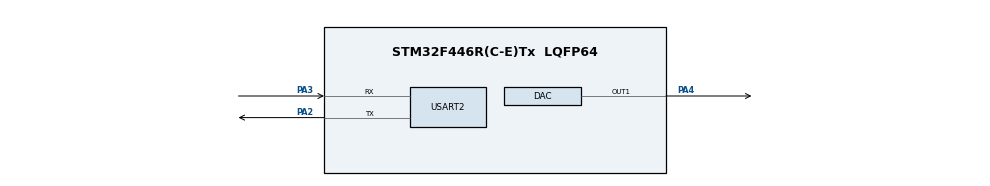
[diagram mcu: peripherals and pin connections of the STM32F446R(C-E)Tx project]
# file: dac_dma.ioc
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DAC.DAC_Trigger=DAC_TRIGGER_T6_TRGO
Dma.DAC1.0.Direction=DMA_MEMORY_TO_PERIPH
Dma.DAC1.0.FIFOMode=DMA_FIFOMODE_DISABLE
Dma.DAC1.0.Instance=DMA1_Stream5
Dma.DAC1.0.MemDataAlignment=DMA_MDATAALIGN_HALFWORD
Dma.DAC1.0.MemInc=DMA_MINC_ENABLE
Dma.DAC1.0.Mode=DMA_CIRCULAR
Dma.DAC1.0.PeriphDataAlignment=DMA_PDATAALIGN_HALFWORD
Dma.DAC1.0.PeriphInc=DMA_PINC_DISABLE
Dma.DAC1.0.Priority=DMA_PRIORITY_LOW
Dma.Request0=DAC1
Mcu.Family=STM32F4
Mcu.Name=STM32F446R(C-E)Tx
Mcu.Package=LQFP64
NVIC.DMA1_Stream5_IRQn=true\:0\:0\:false\:false\:true\:false\:true\:true
NVIC.PriorityGroup=NVIC_PRIORITYGROUP_4
NVIC.TIM6_DAC_IRQn=true\:0\:0\:false\:false\:true\:true\:true\:true
PA13.Mode=Serial_Wire
PA13.Signal=SYS_JTMS-SWDIO
PA14.Mode=Serial_Wire
PA14.Signal=SYS_JTCK-SWCLK
PA2.Mode=Asynchronous
PA2.Signal=USART2_TX
PA3.Mode=Asynchronous
PA3.Signal=USART2_RX
PA4.Signal=COMP_DAC1_group
ProjectManager.HeapSize=0x200
ProjectManager.StackSize=0x400
ProjectManager.TargetToolchain=STM32CubeIDE
RCC.CortexFreq_Value=16000000
RCC.USBFreq_Value=96000000
RCC.VCOOutputFreq_Value=192000000
SH.COMP_DAC1_group.0=DAC_OUT1,DAC_OUT1
TIM6.Period=999
TIM6.Prescaler=15
TIM6.TIM_MasterOutputTrigger=TIM_TRGO_UPDATE
USART2.VirtualMode=VM_ASYNC
VP_TIM6_VS_ClockSourceINT.Mode=Enable_Timer
board=custom

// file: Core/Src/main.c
/* USER CODE BEGIN Header */
/**
  ******************************************************************************
  * @file           : main.c
  * @brief          : Main program body
  ******************************************************************************
  * @attention
  *
  * Copyright (c) 2026 STMicroelectronics.
  * All rights reserved.
  *
  * This software is licensed under terms that can be found in the LICENSE file
  * in the root directory of this software component.
  * If no LICENSE file comes with this software, it is provided AS-IS.
  *
  ******************************************************************************
  */
/* USER CODE END Header */
#include "main.h"

/* USER CODE BEGIN Includes */

#include <stdio.h>
#include <math.h>

/* USER CODE END Includes */

/* USER CODE BEGIN PD */
#define DMA_BUFFER_SIZE 32
#define SAMPLE_FREQ 10000
#define OUTPUT_MID 2048
/* USER CODE END PD */

DAC_HandleTypeDef hdac;
DMA_HandleTypeDef hdma_dac1;

TIM_HandleTypeDef htim6;

UART_HandleTypeDef huart2;

/* USER CODE BEGIN PV */

volatile uint32_t callbck_cnt = 0;
volatile uint32_t cb_cplt;
volatile uint32_t cb_half;

uint16_t dma_buffer[2 * DMA_BUFFER_SIZE];

float angle = 0;
float angle_change = 10 * (2 * M_PI / SAMPLE_FREQ);
const float two_pi = 2 *M_PI;

/* USER CODE END PV */

void SystemClock_Config(void);
static void MX_GPIO_Init(void);
static void MX_DMA_Init(void);
static void MX_USART2_UART_Init(void);
static void MX_DAC_Init(void);
static void MX_TIM6_Init(void);

/* USER CODE BEGIN 0 */

// Send printf to uart2
int _write(int fd, char* ptr, int len) {
  HAL_StatusTypeDef hstatus;

  if (fd == 1 || fd == 2) {
    hstatus = HAL_UART_Transmit(&huart2, (uint8_t *) ptr, len, HAL_MAX_DELAY);
    if (hstatus == HAL_OK)
      return len;
    else
      return -1;
  }
  return -1;
}

inline void HAL_TIM_PeriodElapsedCallback(TIM_HandleTypeDef *htim) {

	if (htim->Instance == TIM6) {
		++callbck_cnt;
	}
}

static inline void do_dac(uint16_t *buffer) {
	for (int i = 0; i < DMA_BUFFER_SIZE; ++i) {
		buffer[i] = OUTPUT_MID - (OUTPUT_MID * cos(angle));
		angle += angle_change;
		if (angle >= two_pi) {
			angle -= two_pi;
		}
	}

}

inline void HAL_DAC_ConvHalfCpltCallbackCh1(DAC_HandleTypeDef *hdac) {
	++cb_half;
	do_dac(&dma_buffer[0]);
}

inline void HAL_DAC_ConvCpltCallbackCh1(DAC_HandleTypeDef *hdac) {
	++cb_cplt;
	do_dac(&dma_buffer[DMA_BUFFER_SIZE]);
}

/* USER CODE END 0 */

int main(void)
{

  /* MCU Configuration--------------------------------------------------------*/

  /* Reset of all peripherals, Initializes the Flash interface and the Systick. */
  HAL_Init();

  /* Configure the system clock */
  SystemClock_Config();

  /* Initialize all configured peripherals */
  MX_GPIO_Init();
  MX_DMA_Init();
  MX_USART2_UART_Init();
  MX_DAC_Init();
  MX_TIM6_Init();
  /* USER CODE BEGIN 2 */

  printf("\n\n\n\n\r------------\n\rStarting DAC\n\r");

  HAL_TIM_Base_Start_IT(&htim6);

  HAL_DAC_Start_DMA(&hdac, DAC_CHANNEL_1, (uint32_t*) &dma_buffer, 2 * DMA_BUFFER_SIZE, DAC_ALIGN_12B_R);

  /* USER CODE END 2 */

  /* Infinite loop */
  /* USER CODE BEGIN WHILE */

  uint32_t now = 0, next_tick = 1000, loop_count = 0;

  while (1)
  {

	  now = uwTick;

	  if (now >= next_tick) {

	  	 printf("Tick %lu (loop = %lu cb = %lu half = %lu cplt = %lu)\n\r", now / 1000, loop_count, callbck_cnt, cb_half, cb_cplt);

	  	 loop_count = 0;
	  	 next_tick = now + 1000;
	  	 }

	  	 ++loop_count;

    /* USER CODE END WHILE */

  }
}

void SystemClock_Config(void)
{
  RCC_OscInitTypeDef RCC_OscInitStruct = {0};
  RCC_ClkInitTypeDef RCC_ClkInitStruct = {0};

  /** Configure the main internal regulator output voltage
  */
  __HAL_RCC_PWR_CLK_ENABLE();
  __HAL_PWR_VOLTAGESCALING_CONFIG(PWR_REGULATOR_VOLTAGE_SCALE3);

  /** Initializes the RCC Oscillators according to the specified parameters
  * in the RCC_OscInitTypeDef structure.
  */
  RCC_OscInitStruct.OscillatorType = RCC_OSCILLATORTYPE_HSI;
  RCC_OscInitStruct.HSIState = RCC_HSI_ON;
  RCC_OscInitStruct.HSICalibrationValue = RCC_HSICALIBRATION_DEFAULT;
  RCC_OscInitStruct.PLL.PLLState = RCC_PLL_NONE;
  if (HAL_RCC_OscConfig(&RCC_OscInitStruct) != HAL_OK)
  {
    Error_Handler();
  }

  /** Initializes the CPU, AHB and APB buses clocks
  */
  RCC_ClkInitStruct.ClockType = RCC_CLOCKTYPE_HCLK|RCC_CLOCKTYPE_SYSCLK
                              |RCC_CLOCKTYPE_PCLK1|RCC_CLOCKTYPE_PCLK2;
  RCC_ClkInitStruct.SYSCLKSource = RCC_SYSCLKSOURCE_HSI;
  RCC_ClkInitStruct.AHBCLKDivider = RCC_SYSCLK_DIV1;
  RCC_ClkInitStruct.APB1CLKDivider = RCC_HCLK_DIV1;
  RCC_ClkInitStruct.APB2CLKDivider = RCC_HCLK_DIV1;

  if (HAL_RCC_ClockConfig(&RCC_ClkInitStruct, FLASH_LATENCY_0) != HAL_OK)
  {
    Error_Handler();
  }
}

static void MX_DAC_Init(void)
{

  DAC_ChannelConfTypeDef sConfig = {0};

  /** DAC Initialization
  */
  hdac.Instance = DAC;
  if (HAL_DAC_Init(&hdac) != HAL_OK)
  {
    Error_Handler();
  }

  /** DAC channel OUT1 config
  */
  sConfig.DAC_Trigger = DAC_TRIGGER_T6_TRGO;
  sConfig.DAC_OutputBuffer = DAC_OUTPUTBUFFER_ENABLE;
  if (HAL_DAC_ConfigChannel(&hdac, &sConfig, DAC_CHANNEL_1) != HAL_OK)
  {
    Error_Handler();
  }

}

static void MX_TIM6_Init(void)
{

  TIM_MasterConfigTypeDef sMasterConfig = {0};

  htim6.Instance = TIM6;
  htim6.Init.Prescaler = 15;
  htim6.Init.CounterMode = TIM_COUNTERMODE_UP;
  htim6.Init.Period = 999;
  htim6.Init.AutoReloadPreload = TIM_AUTORELOAD_PRELOAD_DISABLE;
  if (HAL_TIM_Base_Init(&htim6) != HAL_OK)
  {
    Error_Handler();
  }
  sMasterConfig.MasterOutputTrigger = TIM_TRGO_UPDATE;
  sMasterConfig.MasterSlaveMode = TIM_MASTERSLAVEMODE_DISABLE;
  if (HAL_TIMEx_MasterConfigSynchronization(&htim6, &sMasterConfig) != HAL_OK)
  {
    Error_Handler();
  }

}

static void MX_USART2_UART_Init(void)
{

  huart2.Instance = USART2;
  huart2.Init.BaudRate = 115200;
  huart2.Init.WordLength = UART_WORDLENGTH_8B;
  huart2.Init.StopBits = UART_STOPBITS_1;
  huart2.Init.Parity = UART_PARITY_NONE;
  huart2.Init.Mode = UART_MODE_TX_RX;
  huart2.Init.HwFlowCtl = UART_HWCONTROL_NONE;
  huart2.Init.OverSampling = UART_OVERSAMPLING_16;
  if (HAL_UART_Init(&huart2) != HAL_OK)
  {
    Error_Handler();
  }

}

static void MX_DMA_Init(void)
{

  /* DMA controller clock enable */
  __HAL_RCC_DMA1_CLK_ENABLE();

  /* DMA interrupt init */
  /* DMA1_Stream5_IRQn interrupt configuration */
  HAL_NVIC_SetPriority(DMA1_Stream5_IRQn, 0, 0);
  HAL_NVIC_EnableIRQ(DMA1_Stream5_IRQn);

}

static void MX_GPIO_Init(void)
{

  /* GPIO Ports Clock Enable */
  __HAL_RCC_GPIOA_CLK_ENABLE();

}

void Error_Handler(void)
{
  __disable_irq();
  while (1)
  {
  }
}
